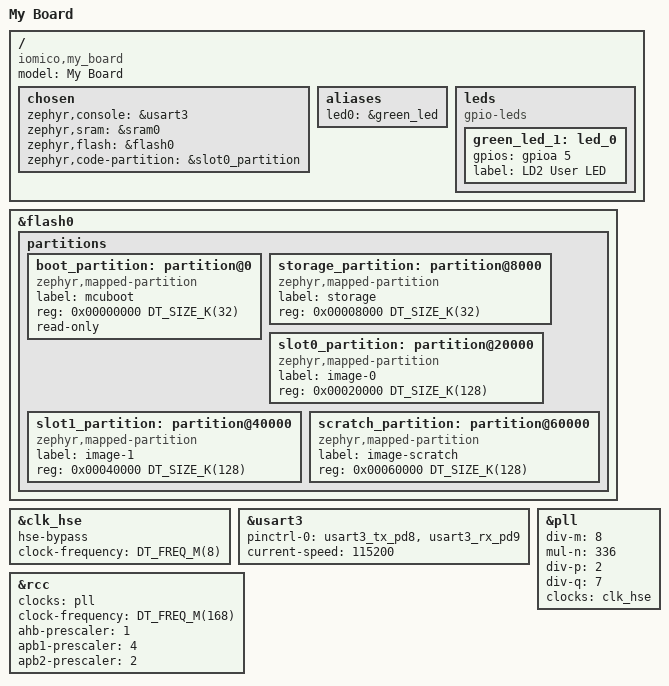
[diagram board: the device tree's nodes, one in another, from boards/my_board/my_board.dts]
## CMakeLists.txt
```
cmake_minimum_required(VERSION 3.20.0)

list(APPEND BOARD_ROOT ${CMAKE_CURRENT_SOURCE_DIR})
find_package(Zephyr REQUIRED)
project(my_zephyr_app)

target_sources(app PRIVATE
	src/main.cpp
	boards/my_board/board.c
)
```

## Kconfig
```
source "Kconfig.zephyr"

menu "LED Application"

config LED_BLINK_TIME_MS
    int "LED blink time (ms)"
    default 1000
    range 500 2000
    help
        Set the LED blink time in milliseconds.

endmenu
```

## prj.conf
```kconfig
CONFIG_GPIO=y
CONFIG_LOG=y
CONFIG_LED_BLINK_TIME_MS=1000
```

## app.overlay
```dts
/ {
    leds {
        compatible = "gpio-leds";

        red_led: red_led {
            gpios = <&gpiob 0 GPIO_ACTIVE_HIGH>;
            label = "External Red LED";
        };
    };

    aliases {
        ext-red-led = &red_led;
    };
};
```

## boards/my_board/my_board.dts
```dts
/dts-v1/;
#include <st/f4/stm32f446Xe.dtsi>
#include <st/f4/stm32f446z(c-e)tx-pinctrl.dtsi>

/ {
	model = "My Board";
	compatible = "iomico,my_board";

	chosen {
		zephyr,console = &usart3;
		zephyr,sram = &sram0;
		zephyr,flash = &flash0;
		zephyr,code-partition = &slot0_partition;
	};

	aliases {
		led0 = &green_led;
	};

	leds: leds {
		compatible = "gpio-leds";

		green_led_1: led_0 {
			gpios = <&gpioa 5 GPIO_ACTIVE_HIGH>;
			label = "LD2 User LED";
		};
	};

	};

&flash0 {
	partitions {
		#address-cells = <1>;
		#size-cells = <1>;
		ranges;

		/* Sectors 0 and 1 (2x16kByte) */
		boot_partition: partition@0 {
			compatible = "zephyr,mapped-partition";
			label = "mcuboot";
			reg = <0x00000000 DT_SIZE_K(32)>;
			read-only;
		};

		/* Sectors 2 and 3 (2x16kByte) */
		storage_partition: partition@8000 {
			compatible = "zephyr,mapped-partition";
			label = "storage";
			reg = <0x00008000 DT_SIZE_K(32)>;
		};

		/* Sector 4 (64kByte): spare/unused */

		/* Sector 5 (128kByte) */
		slot0_partition: partition@20000 {
			compatible = "zephyr,mapped-partition";
			label = "image-0";
			reg = <0x00020000 DT_SIZE_K(128)>;
		};

		/* Sector 6 (128kByte) */
		slot1_partition: partition@40000 {
			compatible = "zephyr,mapped-partition";
			label = "image-1";
			reg = <0x00040000 DT_SIZE_K(128)>;
		};

		/* Sector 7 (128kByte) */
		scratch_partition: partition@60000 {
			compatible = "zephyr,mapped-partition";
			label = "image-scratch";
			reg = <0x00060000 DT_SIZE_K(128)>;
		};
	};
};

&clk_hse {
	hse-bypass;
	clock-frequency = <DT_FREQ_M(8)>;
	status = "okay";
};

&usart3 {
	pinctrl-0 = <&usart3_tx_pd8 &usart3_rx_pd9>;
	pinctrl-names = "default";
	current-speed = <115200>;
	status = "okay";
};

&pll {
	div-m = <8>;
	mul-n = <336>;
	div-p = <2>;
	div-q = <7>;
	clocks = <&clk_hse>;
	status = "okay";
};

&rcc {
	clocks = <&pll>;
	clock-frequency = <DT_FREQ_M(168)>;
	ahb-prescaler = <1>;
	apb1-prescaler = <4>;
	apb2-prescaler = <2>;
};
```

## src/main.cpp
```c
#include <zephyr/drivers/gpio.h>
#include <zephyr/kernel.h>
#include <zephyr/sys/printk.h>

static const gpio_dt_spec status_led = GPIO_DT_SPEC_GET(DT_ALIAS(led0), gpios);

int main(void)
{
    if (!gpio_is_ready_dt(&status_led)) {
        printk("LED GPIO is not ready\n");
        return 0;
    }

    int ret = gpio_pin_configure_dt(&status_led, GPIO_OUTPUT_INACTIVE);
    if (ret < 0) {
        printk("LED GPIO configure failed: %d\n", ret);
        return 0;
    }

    printk("Hello World!\n");

    while (true) {
        ret = gpio_pin_toggle_dt(&status_led);
        if (ret < 0) {
            printk("LED GPIO toggle failed: %d\n", ret);
            return 0;
        }
        k_sleep(K_SECONDS(1));
    }

}
```
